AUTOSAR XML (schema 4-3-0)
package /ComponentTypes
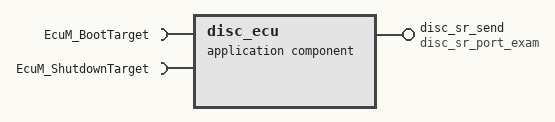
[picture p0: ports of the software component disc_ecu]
  application sw component type disc_ecu
    provide port disc_sr_send: nonqueued-sender-com-spec{data-element=disc_ecu_test, init-value=0}, provided-interface=disc_sr_port_exam
    require port EcuM_BootTarget: required-com-specs=[GetBootTarget, SelectBootTarget], required-interface=EcuM_BootTarget
    require port EcuM_ShutdownTarget: required-com-specs=[GetLastShutdownTarget, GetShutdownCause, GetShutdownTarget, SelectShutdownCause, SelectShutdownTarget], required-interface=EcuM_ShutdownTarget
    behavior disc_ecu_InternalBehavior
      4 x timing event:
        TMT_Core0_Task_100ms: start-on-event=Core0_Task_100ms, period=0.1
        TMT_10ms_disc_ecu_main: start-on-event=Core0_Task_10ms, period=0.01
        TMT_Core0_Task_20ms: start-on-event=Core0_Task_20ms, period=0.02
        TMT_Core0_Task_50ms: start-on-event=Core0_Task_50ms, period=0.05
      port-api-options:
        enable-take-address=false, error-handling=NO-TRANSFORMER-ERROR-HANDLING, indirect-api=false, port=EcuM_BootTarget
        enable-take-address=false, error-handling=NO-TRANSFORMER-ERROR-HANDLING, indirect-api=false, port=EcuM_ShutdownTarget
      4 x runnable:
        Core0_Task_100ms
        Core0_Task_10ms  # This is main runnable for discovery ecu
        Core0_Task_20ms
        Core0_Task_50ms
  swc implementation disc_ecu_Implementation: behavior=disc_ecu_InternalBehavior
    code-descriptors:
      code Default: artifact-descriptors=autosar-engineering-object={short-label=Default, category=SWSRC}
